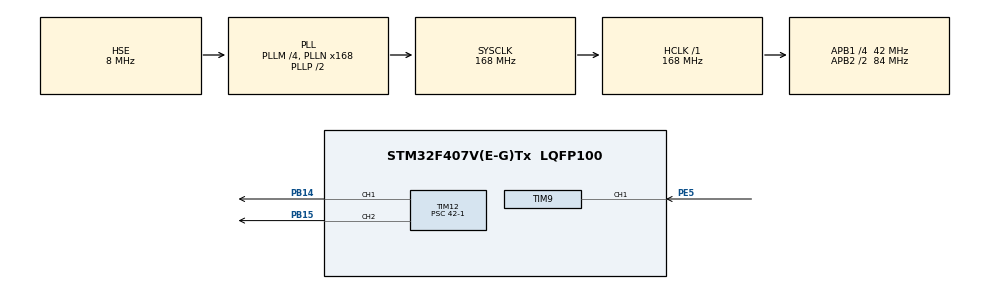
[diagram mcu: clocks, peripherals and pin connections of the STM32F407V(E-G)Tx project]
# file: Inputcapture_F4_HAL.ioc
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Mcu.Family=STM32F4
Mcu.Name=STM32F407V(E-G)Tx
Mcu.Package=LQFP100
NVIC.PriorityGroup=NVIC_PRIORITYGROUP_4
NVIC.TIM1_BRK_TIM9_IRQn=true\:0\:0\:false\:false\:true\:true
PA13.Mode=Serial_Wire
PA13.Signal=SYS_JTMS-SWDIO
PA14.Mode=Serial_Wire
PA14.Signal=SYS_JTCK-SWCLK
PB14.Signal=S_TIM12_CH1
PB15.Signal=S_TIM12_CH2
PE5.Signal=S_TIM9_CH1
PH0-OSC_IN.Mode=HSE-External-Oscillator
PH0-OSC_IN.Signal=RCC_OSC_IN
PH1-OSC_OUT.Mode=HSE-External-Oscillator
PH1-OSC_OUT.Signal=RCC_OSC_OUT
ProjectManager.HeapSize=0x200
ProjectManager.StackSize=0x400
ProjectManager.TargetToolchain=Other Toolchains (GPDSC)
RCC.48MHZClocksFreq_Value=84000000
RCC.AHBFreq_Value=168000000
RCC.APB1CLKDivider=RCC_HCLK_DIV4
RCC.APB1Freq_Value=42000000
RCC.APB1TimFreq_Value=84000000
RCC.APB2CLKDivider=RCC_HCLK_DIV2
RCC.APB2Freq_Value=84000000
RCC.APB2TimFreq_Value=168000000
RCC.CortexFreq_Value=168000000
RCC.HCLKFreq_Value=168000000
RCC.HSE_VALUE=8000000
RCC.HSI_VALUE=16000000
RCC.LSE_VALUE=32768
RCC.PLLM=4
RCC.PLLN=168
RCC.PLLSourceVirtual=RCC_PLLSOURCE_HSE
RCC.SYSCLKFreq_VALUE=168000000
RCC.SYSCLKSource=RCC_SYSCLKSOURCE_PLLCLK
RCC.VCOOutputFreq_Value=336000000
SH.S_TIM12_CH1.0=TIM12_CH1,PWM Generation1 CH1
SH.S_TIM12_CH2.0=TIM12_CH2,PWM Generation2 CH2
SH.S_TIM9_CH1.0=TIM9_CH1,PWM_Input_1
TIM12.Channel-PWM\ Generation1\ CH1=TIM_CHANNEL_1
TIM12.Channel-PWM\ Generation2\ CH2=TIM_CHANNEL_2
TIM12.Period=10000
TIM12.Prescaler=42-1
TIM12.Pulse-PWM\ Generation1\ CH1=5000
TIM12.Pulse-PWM\ Generation2\ CH2=4000
TIM9.Period=50000
TIM9.Prescaler=84-1
VP_TIM12_VS_ClockSourceINT.Mode=Internal
VP_TIM9_VS_ClockSourceINT.Mode=Internal
board=custom

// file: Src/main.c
/**
  ******************************************************************************
  * @file           : main.c
  * @brief          : Main program body
  ******************************************************************************
  ** This notice applies to any and all portions of this file
  * that are not between comment pairs USER CODE BEGIN and
  * USER CODE END. Other portions of this file, whether
  * inserted by the user or by software development tools
  * are owned by their respective copyright owners.
  *
  * COPYRIGHT(c) 2019 STMicroelectronics
  *
  * Redistribution and use in source and binary forms, with or without modification,
  * are permitted provided that the following conditions are met:
  *   1. Redistributions of source code must retain the above copyright notice,
  *      this list of conditions and the following disclaimer.
  *   2. Redistributions in binary form must reproduce the above copyright notice,
  *      this list of conditions and the following disclaimer in the documentation
  *      and/or other materials provided with the distribution.
  *   3. Neither the name of STMicroelectronics nor the names of its contributors
  *      may be used to endorse or promote products derived from this software
  *      without specific prior written permission.
  *
  * THIS SOFTWARE IS PROVIDED BY THE COPYRIGHT HOLDERS AND CONTRIBUTORS "AS IS"
  * AND ANY EXPRESS OR IMPLIED WARRANTIES, INCLUDING, BUT NOT LIMITED TO, THE
  * IMPLIED WARRANTIES OF MERCHANTABILITY AND FITNESS FOR A PARTICULAR PURPOSE ARE
  * DISCLAIMED. IN NO EVENT SHALL THE COPYRIGHT HOLDER OR CONTRIBUTORS BE LIABLE
  * FOR ANY DIRECT, INDIRECT, INCIDENTAL, SPECIAL, EXEMPLARY, OR CONSEQUENTIAL
  * DAMAGES (INCLUDING, BUT NOT LIMITED TO, PROCUREMENT OF SUBSTITUTE GOODS OR
  * SERVICES; LOSS OF USE, DATA, OR PROFITS; OR BUSINESS INTERRUPTION) HOWEVER
  * CAUSED AND ON ANY THEORY OF LIABILITY, WHETHER IN CONTRACT, STRICT LIABILITY,
  * OR TORT (INCLUDING NEGLIGENCE OR OTHERWISE) ARISING IN ANY WAY OUT OF THE USE
  * OF THIS SOFTWARE, EVEN IF ADVISED OF THE POSSIBILITY OF SUCH DAMAGE.
  *
  ******************************************************************************
  */
#include "main.h"
#include "stm32f4xx_hal.h"

TIM_HandleTypeDef htim9;
TIM_HandleTypeDef htim12;

/* USER CODE BEGIN PV */
/* Private variables ---------------------------------------------------------*/
uint32_t A, B,C=5000;
uint8_t k=0;

/* USER CODE END PV */

void SystemClock_Config(void);
static void MX_GPIO_Init(void);
static void MX_TIM9_Init(void);
static void MX_TIM12_Init(void);

void HAL_TIM_MspPostInit(TIM_HandleTypeDef *htim);

/* USER CODE BEGIN PFP */
/* Private function prototypes -----------------------------------------------*/

/* USER CODE END PFP */

int main(void)
{

  /* MCU Configuration----------------------------------------------------------*/

  /* Reset of all peripherals, Initializes the Flash interface and the Systick. */
  HAL_Init();

  /* Configure the system clock */
  SystemClock_Config();

  /* Initialize all configured peripherals */
  MX_GPIO_Init();
  MX_TIM9_Init();
  MX_TIM12_Init();
  /* USER CODE BEGIN 2 */
	HAL_TIM_Base_Start(&htim9);
	HAL_TIM_IC_Start_IT(&htim9, TIM_CHANNEL_1);
	HAL_TIM_IC_Start_IT(&htim9, TIM_CHANNEL_2);
	HAL_TIM_Base_Start(&htim12);
	HAL_TIM_PWM_Start(&htim12, TIM_CHANNEL_1);

	__HAL_TIM_SET_COMPARE(&htim12, TIM_CHANNEL_1, 5000);
	//TIM_SET_CAPTUREPOLARITY(__HANDLE__, __CHANNEL__, __POLARITY__)
  /* USER CODE END 2 */

  /* Infinite loop */
  while (1)
  {

  /* USER CODE BEGIN 3 */
	  if (k == 1)
	  {
		  k = 0;
		  __HAL_TIM_SET_COMPARE(&htim12, TIM_CHANNEL_1, C);
	  }
	  //A = __HAL_TIM_GET_COMPARE(&htim9, TIM_CHANNEL_1);
	//  B = __HAL_TIM_GET_COMPARE(&htim9, TIM_CHANNEL_2);
  }
  /* USER CODE END 3 */

}

void SystemClock_Config(void)
{

  RCC_OscInitTypeDef RCC_OscInitStruct;
  RCC_ClkInitTypeDef RCC_ClkInitStruct;

    /**Configure the main internal regulator output voltage
    */
  __HAL_RCC_PWR_CLK_ENABLE();

  __HAL_PWR_VOLTAGESCALING_CONFIG(PWR_REGULATOR_VOLTAGE_SCALE1);

    /**Initializes the CPU, AHB and APB busses clocks
    */
  RCC_OscInitStruct.OscillatorType = RCC_OSCILLATORTYPE_HSE;
  RCC_OscInitStruct.HSEState = RCC_HSE_ON;
  RCC_OscInitStruct.PLL.PLLState = RCC_PLL_ON;
  RCC_OscInitStruct.PLL.PLLSource = RCC_PLLSOURCE_HSE;
  RCC_OscInitStruct.PLL.PLLM = 4;
  RCC_OscInitStruct.PLL.PLLN = 168;
  RCC_OscInitStruct.PLL.PLLP = RCC_PLLP_DIV2;
  RCC_OscInitStruct.PLL.PLLQ = 4;
  if (HAL_RCC_OscConfig(&RCC_OscInitStruct) != HAL_OK)
  {
    _Error_Handler(__FILE__, __LINE__);
  }

    /**Initializes the CPU, AHB and APB busses clocks
    */
  RCC_ClkInitStruct.ClockType = RCC_CLOCKTYPE_HCLK|RCC_CLOCKTYPE_SYSCLK
                              |RCC_CLOCKTYPE_PCLK1|RCC_CLOCKTYPE_PCLK2;
  RCC_ClkInitStruct.SYSCLKSource = RCC_SYSCLKSOURCE_PLLCLK;
  RCC_ClkInitStruct.AHBCLKDivider = RCC_SYSCLK_DIV1;
  RCC_ClkInitStruct.APB1CLKDivider = RCC_HCLK_DIV4;
  RCC_ClkInitStruct.APB2CLKDivider = RCC_HCLK_DIV2;

  if (HAL_RCC_ClockConfig(&RCC_ClkInitStruct, FLASH_LATENCY_5) != HAL_OK)
  {
    _Error_Handler(__FILE__, __LINE__);
  }

    /**Configure the Systick interrupt time
    */
  HAL_SYSTICK_Config(HAL_RCC_GetHCLKFreq()/1000);

    /**Configure the Systick
    */
  HAL_SYSTICK_CLKSourceConfig(SYSTICK_CLKSOURCE_HCLK);

  /* SysTick_IRQn interrupt configuration */
  HAL_NVIC_SetPriority(SysTick_IRQn, 0, 0);
}

/* TIM9 init function */
static void MX_TIM9_Init(void)
{

  TIM_ClockConfigTypeDef sClockSourceConfig;
  TIM_SlaveConfigTypeDef sSlaveConfig;
  TIM_IC_InitTypeDef sConfigIC;

  htim9.Instance = TIM9;
  htim9.Init.Prescaler = 84-1;
  htim9.Init.CounterMode = TIM_COUNTERMODE_UP;
  htim9.Init.Period = 50000;
  htim9.Init.ClockDivision = TIM_CLOCKDIVISION_DIV1;
  if (HAL_TIM_Base_Init(&htim9) != HAL_OK)
  {
    _Error_Handler(__FILE__, __LINE__);
  }

  sClockSourceConfig.ClockSource = TIM_CLOCKSOURCE_INTERNAL;
  if (HAL_TIM_ConfigClockSource(&htim9, &sClockSourceConfig) != HAL_OK)
  {
    _Error_Handler(__FILE__, __LINE__);
  }

  if (HAL_TIM_IC_Init(&htim9) != HAL_OK)
  {
    _Error_Handler(__FILE__, __LINE__);
  }

  sSlaveConfig.SlaveMode = TIM_SLAVEMODE_RESET;
  sSlaveConfig.InputTrigger = TIM_TS_TI1FP1;
  sSlaveConfig.TriggerPolarity = TIM_INPUTCHANNELPOLARITY_RISING;
  sSlaveConfig.TriggerPrescaler = TIM_ICPSC_DIV1;
  sSlaveConfig.TriggerFilter = 0;
  if (HAL_TIM_SlaveConfigSynchronization(&htim9, &sSlaveConfig) != HAL_OK)
  {
    _Error_Handler(__FILE__, __LINE__);
  }

  sConfigIC.ICPolarity = TIM_INPUTCHANNELPOLARITY_RISING;
  sConfigIC.ICSelection = TIM_ICSELECTION_DIRECTTI;
  sConfigIC.ICPrescaler = TIM_ICPSC_DIV1;
  sConfigIC.ICFilter = 0;
  if (HAL_TIM_IC_ConfigChannel(&htim9, &sConfigIC, TIM_CHANNEL_1) != HAL_OK)
  {
    _Error_Handler(__FILE__, __LINE__);
  }

  sConfigIC.ICPolarity = TIM_INPUTCHANNELPOLARITY_FALLING;
  sConfigIC.ICSelection = TIM_ICSELECTION_INDIRECTTI;
  if (HAL_TIM_IC_ConfigChannel(&htim9, &sConfigIC, TIM_CHANNEL_2) != HAL_OK)
  {
    _Error_Handler(__FILE__, __LINE__);
  }

}

/* TIM12 init function */
static void MX_TIM12_Init(void)
{

  TIM_ClockConfigTypeDef sClockSourceConfig;
  TIM_OC_InitTypeDef sConfigOC;

  htim12.Instance = TIM12;
  htim12.Init.Prescaler = 84-1;
  htim12.Init.CounterMode = TIM_COUNTERMODE_UP;
  htim12.Init.Period = 20000-1;
  htim12.Init.ClockDivision = TIM_CLOCKDIVISION_DIV1;
  if (HAL_TIM_Base_Init(&htim12) != HAL_OK)
  {
    _Error_Handler(__FILE__, __LINE__);
  }

  sClockSourceConfig.ClockSource = TIM_CLOCKSOURCE_INTERNAL;
  if (HAL_TIM_ConfigClockSource(&htim12, &sClockSourceConfig) != HAL_OK)
  {
    _Error_Handler(__FILE__, __LINE__);
  }

  if (HAL_TIM_PWM_Init(&htim12) != HAL_OK)
  {
    _Error_Handler(__FILE__, __LINE__);
  }

  sConfigOC.OCMode = TIM_OCMODE_PWM1;
  sConfigOC.Pulse = 5000;
  sConfigOC.OCPolarity = TIM_OCPOLARITY_HIGH;
  sConfigOC.OCFastMode = TIM_OCFAST_DISABLE;
  if (HAL_TIM_PWM_ConfigChannel(&htim12, &sConfigOC, TIM_CHANNEL_1) != HAL_OK)
  {
    _Error_Handler(__FILE__, __LINE__);
  }

  sConfigOC.Pulse = 4000;
  if (HAL_TIM_PWM_ConfigChannel(&htim12, &sConfigOC, TIM_CHANNEL_2) != HAL_OK)
  {
    _Error_Handler(__FILE__, __LINE__);
  }

  HAL_TIM_MspPostInit(&htim12);

}

/** Configure pins as
        * Analog
        * Input
        * Output
        * EVENT_OUT
        * EXTI
*/
static void MX_GPIO_Init(void)
{

  /* GPIO Ports Clock Enable */
  __HAL_RCC_GPIOE_CLK_ENABLE();
  __HAL_RCC_GPIOH_CLK_ENABLE();
  __HAL_RCC_GPIOB_CLK_ENABLE();
  __HAL_RCC_GPIOA_CLK_ENABLE();

}

/* USER CODE BEGIN 4 */
void HAL_TIM_IC_CaptureCallback(TIM_HandleTypeDef *htim)
  {
	  if (htim->Channel == HAL_TIM_ACTIVE_CHANNEL_1)
	  {
		  A = HAL_TIM_ReadCapturedValue(&htim9, TIM_CHANNEL_1);//����
	  }
	 else if (htim->Channel == HAL_TIM_ACTIVE_CHANNEL_2)
	 {
		  B = HAL_TIM_ReadCapturedValue(&htim9, TIM_CHANNEL_2)+1;//ռ�ձ�
	 }
  }

/* USER CODE END 4 */

void _Error_Handler(char *file, int line)
{
  while(1)
  {
  }
}

/************************ (C) COPYRIGHT STMicroelectronics *****END OF FILE****/
